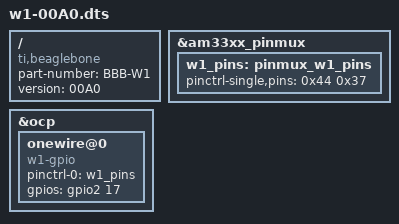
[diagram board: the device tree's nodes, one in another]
/*
* Copyright (C) 2012 Texas Instruments Incorporated - http://www.ti.com/
*
* This program is free software; you can redistribute it and/or modify
* it under the terms of the GNU General Public License version 2 as
* published by the Free Software Foundation.
*/
/dts-v1/;
/plugin/;

/ {
   compatible = "ti,beaglebone", "ti,beaglebone-black";
   part-number = "BBB-W1";
   version = "00A0";

   fragment@0 {
       target = <&am33xx_pinmux>;
       __overlay__ {
            w1_pins: pinmux_w1_pins {
                pinctrl-single,pins = <
                    0x44 0x37     /* gpmc_ad1.gpio1_17, OMAP_PIN_INPUT_PULLUP | OMAP_MUX_MODE7 - w1-gpio */
                >;
            };
       };
   };

   fragment@1 {
       target = <&ocp>;
       __overlay__ {
           onewire@0 {
               compatible      = "w1-gpio";
               pinctrl-names   = "default";
               pinctrl-0       = <&w1_pins>;
               status          = "okay";

               gpios = <&gpio2 17 0>;
           };
       };
   };
};

